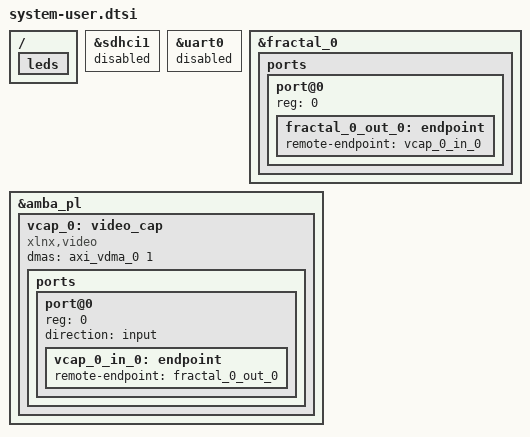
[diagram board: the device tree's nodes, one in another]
/include/ "system-conf.dtsi"
/ {
	/delete-node/ gpio-keys;
	/delete-node/ fixedregulator-mmcsdio;
	/delete-node/ sdio-pwrseq;
	/delete-node/ ina226;
	leds {
		/delete-node/ ds3;
		/delete-node/ ds4;
		/delete-node/ ds5;
	};
};

&sdhci1 {
	status = "disabled";
	/delete-property/ mmc-pwrseq;
	/delete-property/ vqmmc-supply;
	/delete-node/ wifi@2;
};

&uart0 {
	status = "disabled";
	/delete-node/ bluetooth;
};

&fractal_0 {
	ports {
		#address-cells = <1>;
		#size-cells = <0>;

		port@0 {
			reg = <0>;
			fractal_0_out_0: endpoint {
				remote-endpoint = <&vcap_0_in_0>;
			};
		};
	};
};

&amba_pl {
	vcap_0: video_cap {
		compatible = "xlnx,video";
		dmas = <&axi_vdma_0 1>;
		dma-names = "port0";

		ports {
			#address-cells = <1>;
			#size-cells = <0>;

			port@0 {
				reg = <0>;
				direction = "input";
				vcap_0_in_0: endpoint {
					remote-endpoint = <&fractal_0_out_0>;
				};
			};
		};
	};
};
